# STM32MP13xx register map
File version: 1.5
CPU: CA7 r0p0, little endian, MPU, FPU, 4 interrupt priority bits
Registers are 32-bit, read-write, reset 0x0 unless marked. A register's access mark holds for its fields unless they carry their own. Offsets are from the block's base; [hi:lo] are bit positions; {n}, {i} and the like mark numbered series; <NAME> marks a mode.

## SPI1
Base 0x44004000
Same registers: SPI2 0x4000B000, SPI3 0x4000C000, SPI4 0x4C002000, SPI5 0x4C003000
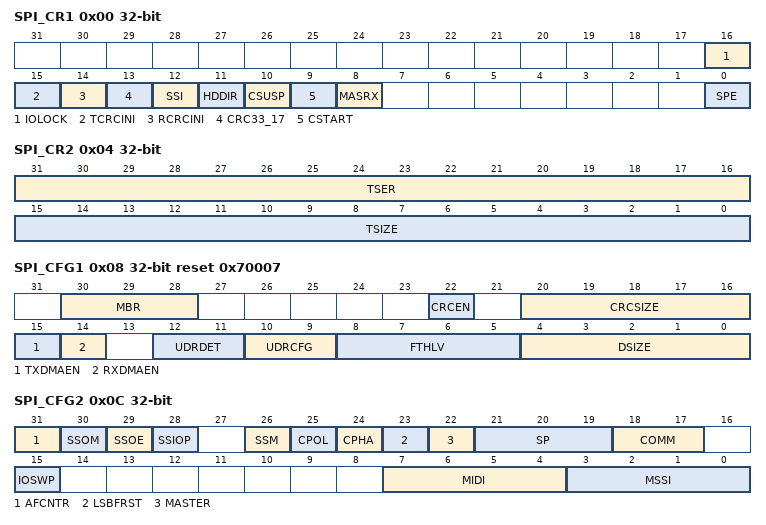
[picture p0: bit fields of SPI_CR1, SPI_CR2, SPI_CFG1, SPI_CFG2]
0x00 SPI_CR1 access per field — SPI/I2S control register 1
  [16] IOLOCK rw — locking the AF configuration of associated IOs This bit is set by software and cleared by hardware whenever SPE bit is changed from 1 to 0. When this bit is set, the SPI_CFG2 register content cannot be modified. This bit can be set when SPI is disabled only else it is write protected. It is cleared and cannot be set when the MODF bit is set.
    0=AF configuration is not locked; 1=AF configuration is locked
  [15] TCRCINI rw — CRC calculation initialization pattern control for transmitter
    0=All zero pattern is applied; 1=All ones pattern is applied
  [14] RCRCINI rw — CRC calculation initialization pattern control for receiver
    0=all zero pattern is applied; 1=all ones pattern is applied
  [13] CRC33_17 rw — 32-bit CRC polynomial configuration
    0=full size (33-bit or 17-bit) CRC polynomial is not used; 1=full size (33-bit or 17-bit) CRC polynomial is used
  [12] SSI rw — internal SS signal input level This bit has an effect only when the SSM bit is set. The value of this bit is forced onto the peripheral SS input and the I/O value of the SS pin is ignored.
  [11] HDDIR rw — Rx/Tx direction at Half-duplex mode In Half-Duplex configuration the HDDIR bit establishes the Rx/Tx direction of the data transfer. This bit is ignored in Full-Duplex or any Simplex configuration.
    0=SPI is Receiver; 1=SPI is transmitter
  [10] CSUSP wo — master suspend request This bit reads as zero. In master mode, when this bit is set by software, CSTART bit is reset at the end of the current frame and SPI communication is suspended. The user has to check SUSP flag to check end of the frame transaction. The master mode communication must be suspended (using this bit or keeping TXDR empty) before disabling the SPI or going to low-power mode. After software suspension, the SUSP flag has to be cleared and the SPI disabled and re-enabled before any next transaction starts.
  [9] CSTART rw — master transfer start This bit is set by software to start an SPI or I2S/PCM communication. In SPI mode, it is cleared by hardware when End Of Transfer (EOT) flag is set or when a transaction suspend request is accepted. In I2S/PCM mode, it is also cleared by hardware as described in the section stop sequence. In SPI mode, the bit is taken into account at master mode only. If transmission is enabled, communication starts or continues only if any data is available in the transmission FIFO.
    0=master transfer is at idle; 1=master transfer is on-going or temporary suspended by automatic suspend
  [8] MASRX rw — master automatic SUSP in Receive mode This bit is set and cleared by software to control continuous SPI transfer in master receiver mode and automatic management in order to avoid overrun condition. When SPI communication is suspended by hardware automatically, it could happen that few bits of next frame are already clocked out due to internal synchronization delay. That is why the automatic suspension is not quite reliable when size of data drops below 8 bits. In this case, a safe suspension can be achieved by combination with delay inserted between data frames applied when MIDI parameter keeps a non zero value; sum of data size and the interleaved SPI cycles must always produce interval at length of 8 SPI clock periods at minimum. After software clearing of the SUSP bit, the communication resumes and continues by subsequent bits transaction without any next constraint. Prior the SUSP bit is cleared, the user must release the RxFIFO space as much as possible by reading out all the data packets available at RxFIFO based on the RXP flag indication to prevent any subsequent suspension.
    0=SPI flow/clock generation is continuous, regardless of overrun condition. (data are lost); 1=SPI flow is suspended temporary on RxFIFO full condition, before reaching overrun condition. The SUSP flag is set when SPI communication is suspended.
  [0] SPE rw — serial peripheral enable This bit is set by and cleared by software. When SPE=1, the SPI data transfer is enabled, the configuration registers SPI_CFG1, SPI_CFG2, CRCPOLY and UDRDR and the IOLOCK bit in SPI_CR1 are write protected. They can be changed only when SPE=0. When SPE=0 any SPI operation is stopped and disabled, all the not cleared requests with enabled interrupt stay pending and propagates the spi_plck clock request, the SS output is deactivated at master, internal state machine is reseted, all the FIFOs content is flushed, CRC calculation initialized, receive data register is read zero. SPE is cleared and cannot be set when MODF error flag is active.
    0=serial peripheral disabled; 1=serial peripheral enabled
0x04 SPI_CR2 — SPI control register 2
  [31:16] TSER — number of data transfer extension to be reload into TSIZE just when a previous number of data stored at TSIZE is transacted This register can be set by software when its content is cleared only. It is cleared by hardware once TSIZE reload is done. The TSER value must be programmed in advance before CTSIZE counter reaches zero otherwise the reload is not taken into account and traffic terminates with normal EOT event.
  [15:0] TSIZE — number of data at current transfer When these bits are changed by software, the SPI must be disabled. The field can be updated by hardware optionally, too, to be reloaded by the TSER value if applicable. Endless transaction is initialized when CSTART is set while zero value is stored at TSIZE. TSIZE cannot be set to 0xFFFF value when CRC is enabled.
0x08 SPI_CFG1 reset 0x70007 — SPI configuration register 1
  [30:28] MBR — master baud rate Note: MBR setting is considered at slave working at TI mode, too (see mode).
    0=SPI master clock/2; 1=SPI master clock/4; 2=SPI master clock/8; 3=SPI master clock/16; 4=SPI master clock/32; 5=SPI master clock/64; 6=SPI master clock/128; 7=SPI master clock/256
  [22] CRCEN — hardware CRC computation enable
    0=CRC calculation disabled; 1=CRC calculation Enabled
  [20:16] CRCSIZE — length of CRC frame to be transacted and compared Most significant bits are taken into account from polynomial calculation when CRC result is transacted or compared. The length of the polynomial is not affected by this setting. ..... The value must be set equal or multiply of data size (DSIZE[4:0]). Its maximum size cannot exceed the DSIZE maximum at the instance. Note: If crc calculation is disabled by CRCEN=0, the CRCSIZE field must be kept at its default setting. Note: The most significant bit at CRCSIZE bit field is reserved at the peripheral instances where the data size is limited to 16-bit.
    {v}={v+1}-bits (v=3..7); 29=30-bits; 30=31-bits; 31=32-bits
  [15] TXDMAEN — Tx DMA stream enable
    0=Tx DMA disabled; 1=Tx DMA enabled
  [14] RXDMAEN — Rx DMA stream enable
    0=Rx-DMA disabled; 1=Rx-DMA enabled
  [12:11] UDRDET — detection of underrun condition at slave transmitter For more details see underrun condition.
    0=underrun is detected at begin of data frame (no protection of 1-st bit); 1=underrun is detected at end of last data frame; 2=underrun is detected by begin of active SS signal
  [10:9] UDRCFG — behavior of slave transmitter at underrun condition When slave is configured at transmit only mode (COMM[1:0]=01), slave repeats all zeros pattern at UDRCFG[1:0]=01 setting. For more details see underrun condition.
    0=slave sends a constant pattern defined by the user at SPI_UDRDR register; 1=slave repeats lastly received data frame from master; 2=slave repeats its lastly transmitted data frame
  [8:5] FTHLV — FIFO threshold level Defines number of data frames at single data packet. The size of the packet must not exceed 1/2 of FIFO space. SPI interface is more efficient if configured packet sizes are aligned with data register access parallelism: If SPI data register is accessed as a 16-bit register and DSIZE<=8bit, better to select FTHLV=2, 4, 6 etc, If SPI data register is accessed as a 32-bit register and DSIZE>8bit, better to select FTHLV=2, 4, 6 etc, while if DSIZE<=8bit, better to select FTHLV=4, 8, 12 etc
    {v}={v+1}-data (v=0..15)
  [4:0] DSIZE — number of bits in at single SPI data frame ..... Note: The most significant bit at DSIZE bit field is reserved at the peripheral instances where data size is limited to 16-bit.
    {v}={v+1}-bits (v=3..7); 29=30-bits; 30=31-bits; 31=32-bits
0x0C SPI_CFG2 — SPI configuration register 2
  [31] AFCNTR — alternate function GPIOs control This bit is taken into account when SPE=0 only When SPI master has to be disabled temporary for a specific configuration reason (e.g. CRC reset, CPHA or HDDIR change) setting this bit prevents any glitches on the associated outputs configured at alternate function mode by keeping them forced at state corresponding the current SPI configuration. This bit must be never used at slave mode as any slave transmitter must not force its MISO output once the SPI is disabled. Note: This bit can be also used in PCM and I2S modes.
    0=the peripheral takes no control of GPIOs while it is disabled; 1=the peripheral keeps always control of all associated GPIOs
  [30] SSOM — SS output management in master mode This bit is taken into account in master mode when SSOE is enabled. It allows to configure SS output between two consecutive data transfers.
    0=SS is kept at active level till data transfer is completed, it becomes inactive with EOT flag; 1=SPI data frames are interleaved with SS non active pulses when MIDI[3:0]>1
  [29] SSOE — SS output enable This bit is taken into account at master mode only
    0=SS output is disabled and the SPI can work in multi-master configuration; 1=SS output is enabled. The SPI cannot work in a multi-master environment. It forces the SS pin at inactive level after the transfer is completed or SPI is disabled with respect to SSOM, MIDI, MSSI, SSIOP bits setting
  [28] SSIOP — SS input/output polarity
    0=low level is active for SS signal; 1=high level is active for SS signal
  [26] SSM — software management of SS signal input When master uses hardware SS output (SSM=0 and SSOE=1), the SS signal input is forced to non active state internally to prevent master mode fault error.
    0=SS input value is determined by the SS PAD; 1=SS input value is determined by the SSI bit
  [25] CPOL — clock polarity
    0=SCK signal is at 0 when idle; 1=SCK signal is at 1 when idle
  [24] CPHA — clock phase
    0=the first clock transition is the first data capture edge; 1=the second clock transition is the first data capture edge
  [23] LSBFRST — data frame format Note: This bit can be also used in PCM and I2S modes.
    0=MSB transmitted first; 1=LSB transmitted first
  [22] MASTER — SPI master
    0=SPI Slave; 1=SPI Master
  [21:19] SP — Serial protocol others: Reserved, must not be used
    0=SPI Motorola; 1=SPI TI
  [18:17] COMM — SPI communication mode
    0=full-duplex; 1=simplex transmitter; 2=simplex receiver; 3=half-duplex
  [15] IOSWP — swap functionality of MISO and MOSI pins When this bit is set, the function of MISO and MOSI pins alternate functions are inverted. Original MISO pin becomes MOSI and original MOSI pin becomes MISO. Note: This bit can be also used in PCM and I2S modes.
    0=no swap; 1=MOSI and MISO are swapped
  [7:4] MIDI — master Inter-Data Idleness Specifies minimum time delay (expressed in SPI clock cycles periods) inserted between two consecutive data frames in master mode. ... Note: This feature is not supported in TI mode.
    0=no delay; 1=1 clock cycle period delay; 15=15 clock cycle periods delay
  [3:0] MSSI — master SS idleness Specifies an extra delay, expressed in number of SPI clock cycle periods, inserted additionally between active edge of SS and first data of a session start in master mode when SSOE is enabled. ... Note: This feature is not supported in TI mode.
    0=no extra delay; 1=1 clock cycle period delay added; 15=15 clock cycle periods delay added
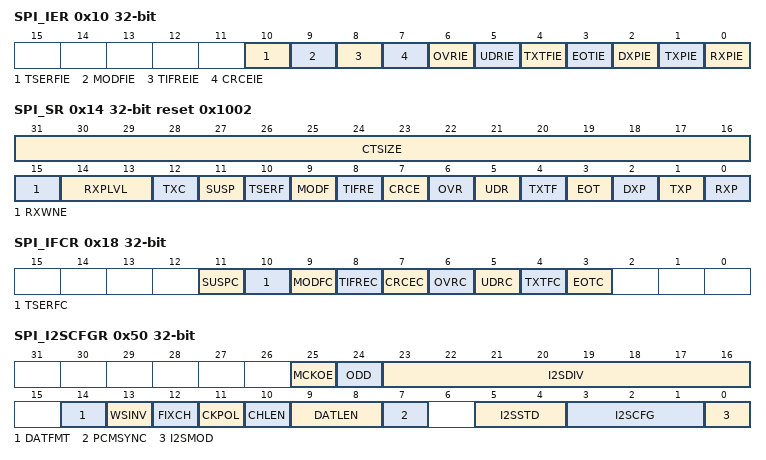
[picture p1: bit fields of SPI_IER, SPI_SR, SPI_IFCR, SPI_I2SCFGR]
0x10 SPI_IER — SPI/I2S interrupt enable register
  [10] TSERFIE — additional number of transactions reload interrupt enable
    0=TSERF interrupt disabled; 1=TSERF interrupt enabled
  [9] MODFIE — mode fault interrupt enable
    0=MODF interrupt disabled; 1=MODF interrupt enabled
  [8] TIFREIE — TIFRE interrupt enable
    0=TIFRE interrupt disabled; 1=TIFRE interrupt enabled
  [7] CRCEIE — CRC error interrupt enable
    0=CRC interrupt disabled; 1=CRC interrupt enabled
  [6] OVRIE — OVR interrupt enable
    0=OVR interrupt disabled; 1=OVR interrupt enabled
  [5] UDRIE — UDR interrupt enable
    0=UDR interrupt disabled; 1=UDR interrupt enabled
  [4] TXTFIE — TXTFIE interrupt enable
    0=TXTF interrupt disabled; 1=TXTF interrupt enabled
  [3] EOTIE — EOT, SUSP and TXC interrupt enable
    0=EOT/SUSP/TXC interrupt disabled; 1=EOT/SUSP/TXC interrupt enabled
  [2] DXPIE — DXP interrupt enabled DXPIE is set by software and cleared by TXTF flag set event.
    0=DXP interrupt disabled; 1=DXP interrupt enabled
  [1] TXPIE — TXP interrupt enable TXPIE is set by software and cleared by TXTF flag set event.
    0=TXP interrupt disabled; 1=TXP interrupt enabled
  [0] RXPIE — RXP Interrupt Enable
    0=RXP interrupt disabled; 1=RXP interrupt enabled
0x14 SPI_SR ro reset 0x1002 — SPI/I2S status register
  [31:16] CTSIZE — number of data frames remaining in current TSIZE session The value is not quite reliable when traffic is ongoing on bus and at LP mode too.
  [15] RXWNE — RxFIFO word not empty Note: This bit value does not depend on DSIZE setting and keeps together with RXPLVL[1:0] information about RxFIFO occupancy by residual data.
    0=less than four bytes of RxFIFO space is occupied by data; 1=at least four bytes of RxFIFO space is occupied by data
  [14:13] RXPLVL — RxFIFO packing leveL When RXWNE=0 and data size is set up to 16-bit, the value gives number of remaining data frames persisting at RxFIFO. (*) optional count when the data size is set up to 8-bit. When the frame size is greater than 16-bit, these bits read as 00. In consequence, the single data frame received at the FIFO cannot be detected neither by RWNE nor by RXPLVL bits if data size is set from 17 to 24 bits. The user then must apply other methods like TSIZE>0 or FTHLV=0.
    0=no next frame is available at RxFIFO; 1=1 frame is available; 2=2 frames are available*; 3=3 frames are available*
  [12] TXC — TxFIFO transmission complete The flag behavior depends on TSIZE setting. When TSIZE=0 the TXC is changed by hardware exclusively and it raises each time the TxFIFO becomes empty and there is no activity on the bus. If TSIZE <>0 there is no specific reason to monitor TXC as it just copies the EOT flag value including its software clearing. The TXC generates an interrupt when EOTIE is set.
    0=Current data transaction is still ongoing, data is available in TxFIFO or last frame transmission is on going; 1=Last TxFIFO frame transmission completed
  [11] SUSP — suspension status In Master mode, SUSP is set by hardware when a CSUSP request is done, either as soon as the current frame is completed after CSUSP request is done or at master automatic suspend receive mode (MASRX bit is set at SPI_CR1 register) on RxFIFO full condition. SUSP generates an interrupt when EOTIE is set. This bit has to be cleared prior SPI is disabled by write 1 to SUSPC bit at SPI_IFCR
    0=SPI not suspended (master mode active or other mode); 1=Master mode is suspended (current frame completed)
  [10] TSERF — additional number of SPI data to be transacted was reload This bit is cleared by write 1 to TSERFC bit at SPI_IFCR or by writing the TSER[15:0] (SPI_CR2) register
    0=no acceptation; 1=additional number of data accepted, current transaction continues
  [9] MODF — mode fault This bit is cleared by write 1 to MODFC bit at SPI_IFCR. When MODF is set, the SPE and IOLOCK bits at the SPI_CR1 register are reset and their setting is blocked.
    0=no mode fault; 1=mode fault detected
  [8] TIFRE — TI frame format error This bit is cleared by write 1 to TIFREC bit at SPI_IFCR
    0=no TI Frame Error; 1=TI Frame Error detected
  [7] CRCE — CRC error This bit is cleared by write 1 to CRCEC bit at SPI_IFCR
    0=no CRC error; 1=CRC error detected
  [6] OVR — overrun This bit is cleared by write 1 to OVRC bit at SPI_IFCR
    0=no overrun; 1=overrun detected
  [5] UDR — underrun at slave transmission mode This bit is cleared by write 1 to UDRC bit at SPI_IFCR Note: UDR flag applies to Slave mode only
    0=no underrun; 1=underrun detected
  [4] TXTF — transmission transfer filled TXTF is set by hardware as soon as all of the data packets in a transfer have been submitted for transmission by application software or DMA, that is when TSIZE number of data have been pushed into the TxFIFO. This bit is cleared by software write 1 to TXTFC bit at SPI_IFCR TXTF flag triggers an interrupt if TXTFIE bit is set. TXTF setting clears the TXIE and DXPIE masks so to off-load application software from calculating when to disable TXP and DXP interrupts.
    0=upload of TxFIFO is on-going or not started; 1=TxFIFO upload is finished
  [3] EOT — end of transfer EOT is set by hardware as soon as a full transfer is complete, that is when TSIZE number of data have been transmitted and/or received on the SPI. EOT is cleared by software write 1 to EOTC bit at SPI_IFCR. EOT flag triggers an interrupt if EOTIE bit is set. If DXP flag is used until TXTF flag is set and DXPIE is cleared, EOT can be used to download the last packets contained into RxFIFO in one-shot. In master, EOT event terminates the data transaction and handles SS output optionally. When CRC is applied, the EOT event is extended over the CRC frame transaction.
    0=transfer is on-going or not started; 1=transfer complete
  [2] DXP — duplex packet The DXP flag is set whenever both TXP and RXP flags are set regardless the SPI mode.
    0=TxFIFO is Full and/or RxFIFO is Empty; 1=Both TxFIFO has space for write and RxFIFO contains for read a single packet at least
  [1] TXP — Tx-packet space available TXP flag is changed by hardware. It monitors overall space currently available at TxFIFO if SPI is enabled. It has to be checked once a complete data packet is stored at TxFIFO.
    0=there is not enough space to locate next data packet at TxFIFO; 1=TxFIFO has enough free location to host 1 data packet
  [0] RXP — Rx-packet available RXP flag is changed by hardware. It monitors number of overall data currently available at RxFIFO if SPI is enabled. It has to be checked once a data packet is completely read out from RxFIFO.
    0=RxFIFO is empty or a not complete data packet is received; 1=RxFIFO contains at least 1 data packet
0x18 SPI_IFCR wo — SPI/I2S interrupt/status flags clear register
  [11] SUSPC — SUSPend flag clear Writing a 1 into this bit clears SUSP flag in the SPI_SR register
  [10] TSERFC — TSERFC flag clear Writing a 1 into this bit clears TSERF flag in the SPI_SR register Note: TSERF is also reset by writing the TSER[15:0] (SPI_CR2) register
  [9] MODFC — mode fault flag clear Writing a 1 into this bit clears MODF flag in the SPI_SR register
  [8] TIFREC — TI frame format error flag clear Writing a 1 into this bit clears TIFRE flag in the SPI_SR register
  [7] CRCEC — CRC error flag clear Writing a 1 into this bit clears CRCE flag in the SPI_SR register
  [6] OVRC — overrun flag clear Writing a 1 into this bit clears OVR flag in the SPI_SR register
  [5] UDRC — underrun flag clear Writing a 1 into this bit clears UDR flag in the SPI_SR register
  [4] TXTFC — transmission Transfer Filled flag clear Writing a 1 into this bit clears TXTF flag in the SPI_SR register
  [3] EOTC — end of transfer flag clear Writing a 1 into this bit clears EOT flag in the SPI_SR register
0x20 SPI_TXDR wo — SPI/I2S transmit data register
  [31:0] TXDR — transmit data register The register serves as an interface with TxFIFO. A write to it accesses TxFIFO. Note: data is always right-aligned. Unused bits are ignored when writing to the register, and read as zero when the register is read. Note: DR can be accessed byte-wise (8-bit access): in this case only one data-byte is written by single access. halfword-wise (16 bit access) in this case 2 data-bytes or 1 halfword-data can be written by single access. word-wise (32 bit access). In this case 4 data-bytes or 2 halfword-data or word-data can be written by single access. Write access of this register less than the configured data size is forbidden.
0x30 SPI_RXDR ro — SPI/I2S receive data register
  [31:0] RXDR — receive data register The register serves as an interface with RxFIFO. When it is read, RxFIFO is accessed. Note: Data is always right-aligned. Unused bits are read as zero when the register is read. Writing to the register is ignored. Note: DR can be accessed byte-wise (8-bit access): in this case only one data-byte is read by single access. halfword-wise (16 bit access) in this case 2 data-bytes or 1 halfword-data can be read by single access word-wise (32 bit access). In this case 4 data-bytes or 2 halfword-data or word-data can be read by single access. Read access of this register less than the configured data size is forbidden.
0x40 SPI_CRCPOLY reset 0x107 — SPI polynomial register
  [31:0] CRCPOLY — CRC polynomial register This register contains the polynomial for the CRC calculation. The default 9-bit polynomial setting 0x107 corresponds to default 8-bit setting of DSIZE. It is compatible with setting 0x07 used at some other ST products with fixed length of the polynomial string where the most significant bit of the string is always kept hidden. Length of the polynomial is given by the most significant bit of the value stored at this register. It has to be set greater than DSIZE. CRC33_17 bit has to be set additionally with CRCPOLY register when DSIZE is configured to maximum 32-bit or 16-bit size and CRC is enabled (to keep polynomial length grater than data size). Bits 31-16 are reserved at the peripheral instances with data size limited to 16-bit. There is no constrain when 32-bit access is applied at these addresses. Reserved bits 31-16 are always read zero while any write to them is ignored.
0x44 SPI_TXCRC ro — SPI transmitter CRC register
  [31:0] TXCRC — CRC register for transmitter When CRC calculation is enabled, the TXCRC[31:0] bits contain the computed CRC value of the subsequently transmitted bytes. CRC calculation is initialized when the CRCEN bit of SPI_CR1 is written to 1 or when a data block is transacted completely. The CRC is calculated serially using the polynomial programmed in the SPI_CRCPOLY register. The number of bits considered at calculation depends on SPI_CRCPOLY register and CRCSIZE bits settings at SPI_CFG1 register. Note: A read to this register when the communication is ongoing could return an incorrect value. Not used for the I2S mode. Bits 31-16 are reserved at the peripheral instances with data size limited to 16-bit. There is no constrain when 32-bit access is applied at these addresses. Reserved bits 31-16 are always read zero while any write to them is ignored. Note: The configuration of CRCSIZE bit field is not taken into account when the content of this register is read by software. No masking is applied for unused bits at this case.
0x48 SPI_RXCRC ro — SPI receiver CRC register
  [31:0] RXCRC — CRC register for receiver When CRC calculation is enabled, the RXCRC[31:0] bits contain the computed CRC value of the subsequently received bytes. CRC calculation is initialized when the CRCEN bit of SPI_CR1 is written to 1 or when a data block is transacted completely. The CRC is calculated serially using the polynomial programmed in the SPI_CRCPOLY register. The number of bits considered at calculation depends on SPI_CRCPOLY register and CRCSIZE bits settings at SPI_CFG1 register. Note: A read to this register when the communication is ongoing could return an incorrect value. Not used for the I2S mode. Bits 31-16 are reserved at the peripheral instances with data size limited to 16-bit. There is no constrain when 32-bit access is applied at these addresses. Reserved bits 31-16 are always read zero while any write to them is ignored. Note: The configuration of CRCSIZE bit field is not taken into account when the content of this register is read by software. No masking is applied for unused bits at this case.
0x4C SPI_UDRDR — SPI underrun data register
  [31:0] UDRDR — data at slave underrun condition The register is taken into account at slave mode and at underrun condition only. The number of bits considered depends on DSIZE bit settings at SPI_CFG1 register. Underrun condition handling depends on setting if UDRDET and UDRCFG bits at SPI_CFG1 register. Bits 31-16 are reserved at the peripheral instances with data size limited to 16-bit. There is no constrain when 32-bit access is applied at these addresses. Reserved bits 31-16 are always read zero while any write to them is ignored.
0x50 SPI_I2SCFGR — SPI/I2S configuration register
  [25] MCKOE — master clock output enable
    0=Master clock output is disabled; 1=Master clock output is enabled
  [24] ODD — odd factor for the prescaler Refer to for details
    0=Real divider value is = I2SDIV *2; 1=Real divider value is = (I2SDIV * 2) + 1
  [23:16] I2SDIV — I2S linear prescaler I2SDIV can take any values except the value 1, when ODD is also equal to 1. Refer to for details
  [14] DATFMT — data format
    0=the data inside the SPI_RXDR or SPI_TXDR are right aligned; 1=the data inside the SPI_RXDR or SPI_TXDR are left aligned
  [13] WSINV — Word select inversion This bit is used to invert the default polarity of WS signal. WS is low. In PCM mode the start of frame is indicated by a rising edge. WS is high. In PCM mode the start of frame is indicated by a falling edge.
    0=in I2S Philips standard, Left channel is transfered when WS is low, and right channel when WS is high. In MSB or LSB justified mode, Left channel is transfered when WS is high, and right channel when; 1=in I2S Philips standard, Left channel is transfered when WS is high, and right channel when WS is low.In MSB or LSB justified mode, Left channel is transfered when WS is low, and right channel when
  [12] FIXCH — fixed channel length in slave
    0=the channel length in slave mode is different from 16 or 32 bits (CHLEN not taken into account); 1=the channel length in slave mode is supposed to be 16 or 32 bits (according to CHLEN)
  [11] CKPOL — serial audio clock polarity
    0=the signals generated by the SPI/I2S (i.e. SDO and WS) are changed on the falling edge of CK and the signals received by the SPI/I2S (i.e. SDI and WS) are read of the rising edge of CK.; 1=the signals generated by the SPI/I2S (i.e. SDO and WS) are changed on the rising edge of CK and the signals received by the SPI/I2S (i.e. SDI and WS) are read of the falling edge of CK.
  [10] CHLEN — channel length (number of bits per audio channel) The bit write operation has a meaning only if DATLEN = 00 otherwise the channel length is fixed to 32-bit by hardware whatever the value filled in.
    0=16-bit wide; 1=32-bit wide
  [9:8] DATLEN — data length to be transferred
    0=16-bit data length; 1=24-bit data length; 2=32-bit data length; 3=not allowed
  [7] PCMSYNC — PCM frame synchronization
    0=short frame synchronization; 1=long frame synchronization
  [5:4] I2SSTD — I2S standard selection For more details on I2S standards, refer to
    0=I2S Philips standard; 1=MSB justified standard (left justified); 2=LSB justified standard (right justified); 3=PCM standard
  [3:1] I2SCFG — I2S configuration mode others, not used
    0=slave - transmit; 1=slave - receive; 2=master - transmit; 3=master - receive; 4=slave - full duplex; 5=master - full duplex
  [0] I2SMOD — I2S mode selection
    0=SPI mode is selected; 1=I2S/PCM mode is selected
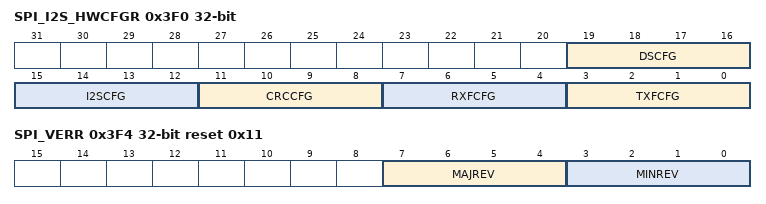
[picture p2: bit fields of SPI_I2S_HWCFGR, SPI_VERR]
0x3F0 SPI_I2S_HWCFGR ro (reset mask 0xFFF00000) — SPI/I2S hardware configuration register
  [19:16] DSCFG — SPI data size configuration All the other combinations are reserved.
    0=data size is configurable from 4-bits to 16-bits; 1=data size is configurable from 4-bits to 32-bits
  [15:12] I2SCFG — I2S configuration All the other combinations are reserved.
    0=I2S support is not implemented; 1=I2S support is implemented
  [11:8] CRCCFG — CRC configuration for SPI All the other combinations are reserved.
    0=CRC support is not implemented; 1=CRC support is implemented
  [7:4] RXFCFG — RxFIFO size 0002: the FIFO size is 4 bytes 0003: the FIFO size is 8 bytes 0004: the FIFO size is 16 bytes 0005: the FIFO size is 32 bytes All the other combinations are reserved.
  [3:0] TXFCFG — TxFIFO size 0002: the FIFO size is 4 bytes 0003: the FIFO size is 8 bytes 0004: the FIFO size is 16 bytes 0005: the FIFO size is 32 bytes All the other combinations are reserved.
0x3F4 SPI_VERR ro reset 0x11 — SPI/I2S version register
  [7:4] MAJREV — major revision of the IP.
  [3:0] MINREV — minor revision of the IP.
0x3F8 SPI_IPIDR ro reset 0x130022 — SPI/I2S identification register
  [31:0] ID — IP identification MCD identification code which identifies the IP.
0x3FC SPI_SIDR ro reset 0xA3C5DD01 — SPI/I2S size identification register
  [31:0] SID — size identification Bits[31:8]: fixed code 0xA3C5DD0 Bits[7:0]: range of address decoding boundary All the other combination are reserved.
    1=1 Kbyte; 2=2 Kbytes; 4=4 Kbytes; 8=8 Kbytes
